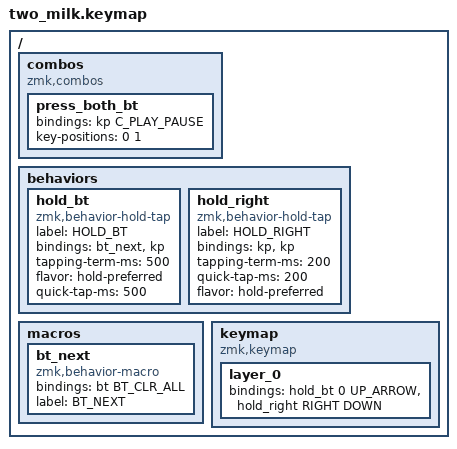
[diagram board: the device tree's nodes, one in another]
#include <behaviors.dtsi>
#include <dt-bindings/zmk/bt.h>
#include <dt-bindings/zmk/keys.h>

/ {
    combos {
        compatible = "zmk,combos";

        press_both_bt {
            bindings = <&kp C_PLAY_PAUSE>;
            key-positions = <0 1>;
        };
    };

    behaviors {
        hold_bt: hold_bt {
            compatible = "zmk,behavior-hold-tap";
            label = "HOLD_BT";
            bindings = <&bt_next>, <&kp>;

            #binding-cells = <2>;
            tapping-term-ms = <500>;
            flavor = "hold-preferred";
            quick-tap-ms = <500>;
        };

        hold_right: hold_right {
            compatible = "zmk,behavior-hold-tap";
            label = "HOLD_RIGHT";
            bindings = <&kp>, <&kp>;

            #binding-cells = <2>;
            tapping-term-ms = <200>;
            quick-tap-ms = <200>;
            flavor = "hold-preferred";
        };
    };

    macros {
        bt_next: bt_next {
            compatible = "zmk,behavior-macro";
            #binding-cells = <0>;
            bindings = <&bt BT_CLR_ALL>;
            label = "BT_NEXT";
        };
    };

    keymap {
        compatible = "zmk,keymap";

        layer_0 {
            bindings = <
&hold_bt 0 UP_ARROW  &hold_right RIGHT DOWN
            >;
        };
    };
};
